AUTOSAR XML (schema 4-2-2)
package /Components
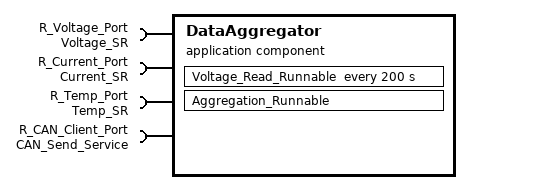
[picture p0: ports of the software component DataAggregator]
  application sw component type DataAggregator
    4 x require port:
      R_Voltage_Port: required-interface=Voltage_SR
      R_Current_Port: required-interface=Current_SR
      R_Temp_Port: required-interface=Temp_SR
      R_CAN_Client_Port: required-interface=CAN_Send_Service
    behavior DataAggregatorBehavior
      data received event Voltage_Input_Received: start-on-event=Voltage_Read_Runnable
      data received event Current_Input_Received: start-on-event=Current_Read_Runnable
      data received event Temp_Input_Received: start-on-event=Temp_Read_Runnable
      timing event Aggregation_Timer: start-on-event=Voltage_Read_Runnable, period=200
      runnable Aggregation_Runnable: minimum-start-interval=200, symbol=DataAggregator_Aggregation_Runnable
        data-receive-point-by-values:
          access Voltage_Access: accessed-variable=R_Voltage_Port.Voltage_Volt
          access Current_Access: accessed-variable=R_Current_Port.Current_Amp
          access Temp_Access: accessed-variable=R_Temp_Port.Temp_Celsius
        data-send-points:
          access BatteryState_Send: accessed-variable=R_CAN_Client_Port.BatteryState
        sync call CAN_Send_Call: operation=R_CAN_Client_Port.SendBatteryState, timeout=20
